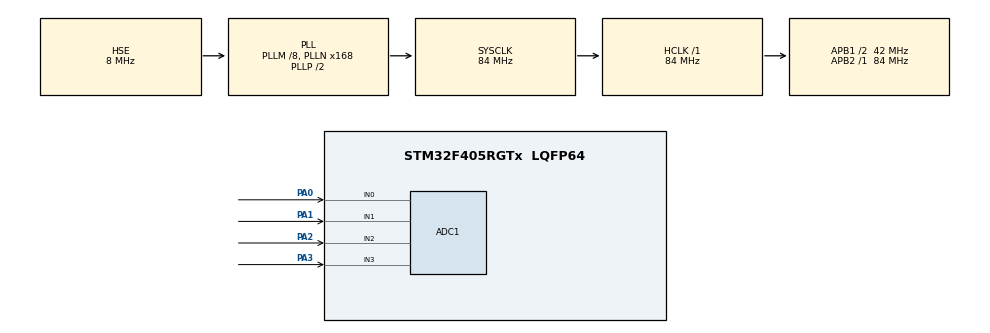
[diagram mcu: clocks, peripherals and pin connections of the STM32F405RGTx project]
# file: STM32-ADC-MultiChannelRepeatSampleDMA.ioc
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ADC1.Channel-1\#ChannelRegularConversion=ADC_CHANNEL_0
ADC1.Channel-2\#ChannelRegularConversion=ADC_CHANNEL_1
ADC1.Channel-3\#ChannelRegularConversion=ADC_CHANNEL_1
ADC1.Channel-4\#ChannelRegularConversion=ADC_CHANNEL_2
ADC1.Channel-5\#ChannelRegularConversion=ADC_CHANNEL_VREFINT
ADC1.ContinuousConvMode=ENABLE
ADC1.EOCSelection=ADC_EOC_SEQ_CONV
ADC1.NbrOfConversion=5
ADC1.NbrOfConversionFlag=1
ADC1.Rank-1\#ChannelRegularConversion=1
ADC1.Rank-2\#ChannelRegularConversion=2
ADC1.Rank-3\#ChannelRegularConversion=3
ADC1.Rank-4\#ChannelRegularConversion=4
ADC1.Rank-5\#ChannelRegularConversion=5
ADC1.SamplingTime-1\#ChannelRegularConversion=ADC_SAMPLETIME_480CYCLES
ADC1.SamplingTime-2\#ChannelRegularConversion=ADC_SAMPLETIME_3CYCLES
ADC1.SamplingTime-3\#ChannelRegularConversion=ADC_SAMPLETIME_3CYCLES
ADC1.SamplingTime-4\#ChannelRegularConversion=ADC_SAMPLETIME_3CYCLES
ADC1.SamplingTime-5\#ChannelRegularConversion=ADC_SAMPLETIME_3CYCLES
ADC1.ScanConvMode=ENABLE
ADC1.master=1
Dma.ADC1.0.Direction=DMA_PERIPH_TO_MEMORY
Dma.ADC1.0.FIFOMode=DMA_FIFOMODE_DISABLE
Dma.ADC1.0.Instance=DMA2_Stream0
Dma.ADC1.0.MemDataAlignment=DMA_MDATAALIGN_WORD
Dma.ADC1.0.MemInc=DMA_MINC_ENABLE
Dma.ADC1.0.Mode=DMA_NORMAL
Dma.ADC1.0.PeriphDataAlignment=DMA_PDATAALIGN_WORD
Dma.ADC1.0.PeriphInc=DMA_PINC_DISABLE
Dma.ADC1.0.Priority=DMA_PRIORITY_LOW
Dma.Request0=ADC1
Mcu.Family=STM32F4
Mcu.Name=STM32F405RGTx
Mcu.Package=LQFP64
NVIC.ADC_IRQn=true\:0\:0\:false\:false\:true\:true\:true\:true
NVIC.DMA2_Stream0_IRQn=true\:0\:0\:false\:false\:true\:false\:true\:true
NVIC.PriorityGroup=NVIC_PRIORITYGROUP_4
PA0-WKUP.Signal=ADCx_IN0
PA1.Signal=ADCx_IN1
PA13.Mode=JTAG_5_pins
PA13.Signal=SYS_JTMS-SWDIO
PA14.Mode=JTAG_5_pins
PA14.Signal=SYS_JTCK-SWCLK
PA15.Mode=JTAG_5_pins
PA15.Signal=SYS_JTDI
PA2.Signal=ADCx_IN2
PA3.Signal=ADCx_IN3
PB3.Mode=JTAG_5_pins
PB3.Signal=SYS_JTDO-SWO
PB4.Mode=JTAG_5_pins
PB4.Signal=SYS_JTRST
PH0-OSC_IN.Mode=HSE-External-Oscillator
PH0-OSC_IN.Signal=RCC_OSC_IN
PH1-OSC_OUT.Mode=HSE-External-Oscillator
PH1-OSC_OUT.Signal=RCC_OSC_OUT
ProjectManager.HeapSize=0x200
ProjectManager.StackSize=0x400
ProjectManager.TargetToolchain=MDK-ARM V5
RCC.48MHZClocksFreq_Value=42000000
RCC.AHBFreq_Value=84000000
RCC.APB1CLKDivider=RCC_HCLK_DIV2
RCC.APB1Freq_Value=42000000
RCC.APB1TimFreq_Value=84000000
RCC.APB2Freq_Value=84000000
RCC.APB2TimFreq_Value=84000000
RCC.CortexFreq_Value=84000000
RCC.HCLKFreq_Value=84000000
RCC.HSE_VALUE=8000000
RCC.HSI_VALUE=16000000
RCC.LSE_VALUE=32768
RCC.PLLM=8
RCC.PLLN=168
RCC.PLLSourceVirtual=RCC_PLLSOURCE_HSE
RCC.SYSCLKFreq_VALUE=84000000
RCC.SYSCLKSource=RCC_SYSCLKSOURCE_PLLCLK
RCC.VCOOutputFreq_Value=168000000
SH.ADCx_IN0.0=ADC1_IN0,IN0
SH.ADCx_IN1.0=ADC1_IN1,IN1
SH.ADCx_IN2.0=ADC1_IN2,IN2
SH.ADCx_IN3.0=ADC1_IN3,IN3
VP_ADC1_Vref_Input.Mode=IN-Vrefint
board=custom

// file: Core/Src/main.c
/* USER CODE BEGIN Header */
/**
  ******************************************************************************
  * @file           : main.c
  * @brief          : Main program body
  ******************************************************************************
  * @attention
  *
  * Copyright (c) 2022 STMicroelectronics.
  * All rights reserved.
  *
  * This software is licensed under terms that can be found in the LICENSE file
  * in the root directory of this software component.
  * If no LICENSE file comes with this software, it is provided AS-IS.
  *
  ******************************************************************************
  */
/* USER CODE END Header */
#include "main.h"
#include "adc.h"
#include "dma.h"
#include "gpio.h"

/* USER CODE BEGIN PD */
#define ADC_Length 100
#define ADC_Repeat	25
/* USER CODE END PD */

/* USER CODE BEGIN PV */
uint8_t ADC_Flag=RESET;
/* USER CODE END PV */

void SystemClock_Config(void);

/* USER CODE BEGIN 0 */
void HAL_ADC_ConvCpltCallback(ADC_HandleTypeDef* hadc)
{
	if(hadc==&hadc1)
	{

		ADC_Flag=SET;

	}

}
/* USER CODE END 0 */

int main(void)
{

  /* MCU Configuration--------------------------------------------------------*/

  /* Reset of all peripherals, Initializes the Flash interface and the Systick. */
  HAL_Init();

  /* Configure the system clock */
  SystemClock_Config();

  /* Initialize all configured peripherals */
  MX_GPIO_Init();
  MX_DMA_Init();
  MX_ADC1_Init();

  /* Infinite loop */
  /* USER CODE BEGIN WHILE */
	volatile uint32_t ADC_Value[ADC_Length];//储存采样的ADC值

	HAL_ADC_Start_DMA(&hadc1,ADC_Value,ADC_Length);//开启采样
  while (1)
  {
		if(ADC_Flag==SET)
		{
			HAL_ADC_Stop_DMA(&hadc1);
			//对采样数据做处理

			ADC_Flag=RESET;//复位标志位
			HAL_ADC_Start_DMA(&hadc1,ADC_Value,ADC_Length);//开启下一次采样
		}
    /* USER CODE END WHILE */

    /* USER CODE BEGIN 3 */
		HAL_Delay(500);
  }
  /* USER CODE END 3 */
}

void SystemClock_Config(void)
{
  RCC_OscInitTypeDef RCC_OscInitStruct = {0};
  RCC_ClkInitTypeDef RCC_ClkInitStruct = {0};

  /** Configure the main internal regulator output voltage
  */
  __HAL_RCC_PWR_CLK_ENABLE();
  __HAL_PWR_VOLTAGESCALING_CONFIG(PWR_REGULATOR_VOLTAGE_SCALE1);

  /** Initializes the RCC Oscillators according to the specified parameters
  * in the RCC_OscInitTypeDef structure.
  */
  RCC_OscInitStruct.OscillatorType = RCC_OSCILLATORTYPE_HSE;
  RCC_OscInitStruct.HSEState = RCC_HSE_ON;
  RCC_OscInitStruct.PLL.PLLState = RCC_PLL_ON;
  RCC_OscInitStruct.PLL.PLLSource = RCC_PLLSOURCE_HSE;
  RCC_OscInitStruct.PLL.PLLM = 8;
  RCC_OscInitStruct.PLL.PLLN = 168;
  RCC_OscInitStruct.PLL.PLLP = RCC_PLLP_DIV2;
  RCC_OscInitStruct.PLL.PLLQ = 4;
  if (HAL_RCC_OscConfig(&RCC_OscInitStruct) != HAL_OK)
  {
    Error_Handler();
  }

  /** Initializes the CPU, AHB and APB buses clocks
  */
  RCC_ClkInitStruct.ClockType = RCC_CLOCKTYPE_HCLK|RCC_CLOCKTYPE_SYSCLK
                              |RCC_CLOCKTYPE_PCLK1|RCC_CLOCKTYPE_PCLK2;
  RCC_ClkInitStruct.SYSCLKSource = RCC_SYSCLKSOURCE_PLLCLK;
  RCC_ClkInitStruct.AHBCLKDivider = RCC_SYSCLK_DIV1;
  RCC_ClkInitStruct.APB1CLKDivider = RCC_HCLK_DIV2;
  RCC_ClkInitStruct.APB2CLKDivider = RCC_HCLK_DIV1;

  if (HAL_RCC_ClockConfig(&RCC_ClkInitStruct, FLASH_LATENCY_2) != HAL_OK)
  {
    Error_Handler();
  }
}

void Error_Handler(void)
{
  __disable_irq();
  while (1)
  {
  }
}
